# ing916 register map
Vendor: INGChips; Series: ing916xx; File version: 522
CPU: CM4 r0p1, little endian, MPU, FPU, VTOR, 5 interrupt priority bits
Registers are 32-bit, read-write, reset 0x0 unless marked. A register's access mark holds for its fields unless they carry their own. Offsets are from the block's base; [hi:lo] are bit positions; {n}, {i} and the like mark numbered series.

## sadc
Base 0x4000F000
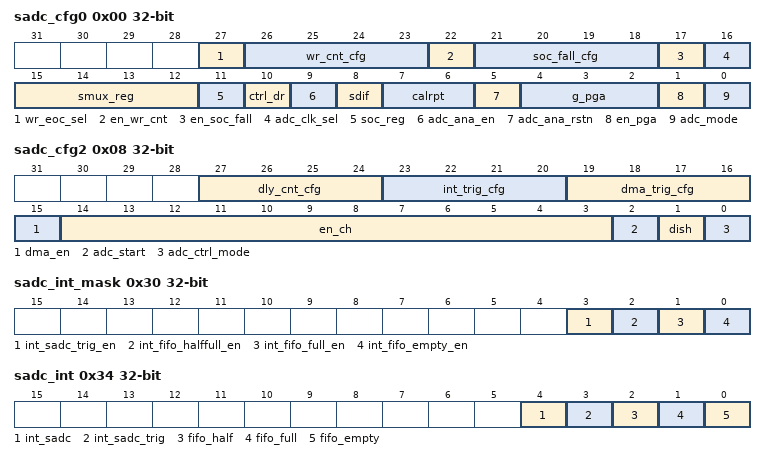
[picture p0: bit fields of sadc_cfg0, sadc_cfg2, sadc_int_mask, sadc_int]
0x00 sadc_cfg0 — reg description:
  [27] wr_eoc_sel — reg description:
  [26:23] wr_cnt_cfg — reg description:
  [22] en_wr_cnt — reg description:
  [21:18] soc_fall_cfg — reg description:
  [17] en_soc_fall — reg description:
  [16] adc_clk_sel — reg description:
  [15:12] smux_reg — reg description:
  [11] soc_reg — reg description:
  [10] ctrl_dr — reg description:
  [9] adc_ana_en — reg description:
  [8] sdif — reg description:
  [7:6] calrpt — reg description:
  [5] adc_ana_rstn — reg description:
  [4:2] g_pga — reg description:
  [1] en_pga — reg description:
  [0] adc_mode — reg description:
0x04 sadc_cfg1 — reg description:
  [31:0] loop_delay
0x08 sadc_cfg2 — reg description:
  [27:24] dly_cnt_cfg — reg description:
  [23:20] int_trig_cfg — reg description:
  [19:16] dma_trig_cfg — reg description:
  [15] dma_en — reg description:
  [14:3] en_ch — reg description:
  [2] adc_start — reg description:
  [1] dish — reg description:
  [0] adc_ctrl_mode — reg description:
0x0C sadc_data — reg description:
  [17:0] sadc_data
0x10 sadc_status0 — reg description:
0x30 sadc_int_mask — reg description:
  [3] int_sadc_trig_en — reg description:
  [2] int_fifo_halffull_en — reg description:
  [1] int_fifo_full_en — reg description:
  [0] int_fifo_empty_en — reg description:
0x34 sadc_int — reg description:
  [4] int_sadc — reg description:
  [3] int_sadc_trig — reg description:
  [2] fifo_half — reg description:
  [1] fifo_full — reg description:
  [0] fifo_empty — reg description:

## aon1_ctrl
Base 0x40102000
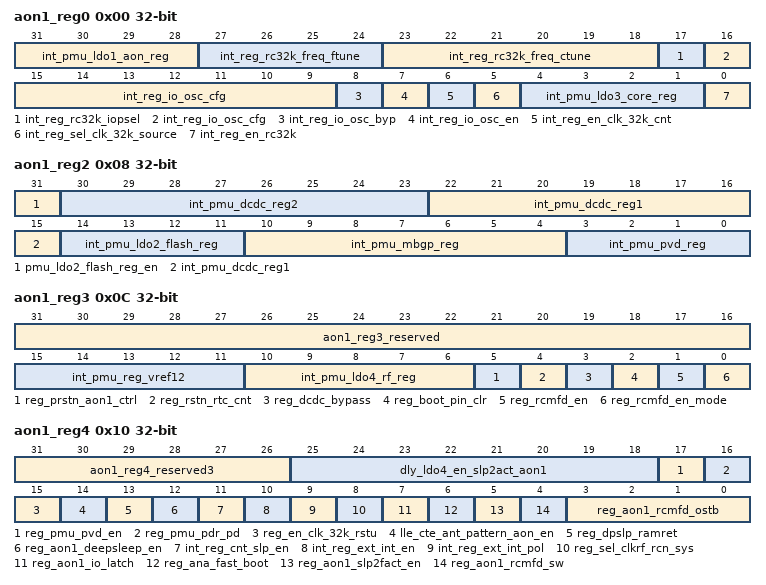
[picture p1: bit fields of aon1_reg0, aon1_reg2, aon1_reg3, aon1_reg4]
0x00 aon1_reg0 — reg description:
  [31:28] int_pmu_ldo1_aon_reg — reg description:
  [27:24] int_reg_rc32k_freq_ftune — reg description:
  [23:18] int_reg_rc32k_freq_ctune — reg description:
  [17] int_reg_rc32k_iopsel — reg description:
  [16:9] int_reg_io_osc_cfg — reg description:
  [8] int_reg_io_osc_byp — reg description:
  [7] int_reg_io_osc_en — reg description:
  [6] int_reg_en_clk_32k_cnt — reg description:
  [5] int_reg_sel_clk_32k_source — reg description:
  [4:1] int_pmu_ldo3_core_reg — reg description:
  [0] int_reg_en_rc32k — reg description:
0x04 aon1_reg1 — reg description:
  [31:0] int_reg_cnt_tgt
0x08 aon1_reg2 — reg description:
  [31] pmu_ldo2_flash_reg_en — reg description:
  [30:23] int_pmu_dcdc_reg2 — reg description:
  [22:15] int_pmu_dcdc_reg1 — reg description:
  [14:11] int_pmu_ldo2_flash_reg — reg description:
  [10:4] int_pmu_mbgp_reg — reg description:
  [3:0] int_pmu_pvd_reg — reg description:
0x0C aon1_reg3 — reg description:
  [31:16] aon1_reg3_reserved — reg description:
  [15:11] int_pmu_reg_vref12 — reg description:
  [10:6] int_pmu_ldo4_rf_reg — reg description:
  [5] reg_prstn_aon1_ctrl — reg description:
  [4] reg_rstn_rtc_cnt — reg description:
  [3] reg_dcdc_bypass — reg description:
  [2] reg_boot_pin_clr — reg description:
  [1] reg_rcmfd_en — reg description:
  [0] reg_rcmfd_en_mode — reg description:
0x10 aon1_reg4 — reg description:
  [31:26] aon1_reg4_reserved3 — reg description:
  [25:18] dly_ldo4_en_slp2act_aon1 — reg description:
  [17] reg_pmu_pvd_en — reg description:
  [16] reg_pmu_pdr_pd — reg description:
  [15] reg_en_clk_32k_rstu — reg description:
  [14] lle_cte_ant_pattern_aon_en — reg description:
  [13] reg_dpslp_ramret — reg description:
  [12] reg_aon1_deepsleep_en — reg description:
  [11] int_reg_cnt_slp_en — reg description:
  [10] int_reg_ext_int_en — reg description:
  [9] int_reg_ext_int_pol — reg description:
  [8] reg_sel_clkrf_rcn_sys — reg description:
  [7] reg_aon1_io_latch — reg description:
  [6] reg_ana_fast_boot — reg description:
  [5] reg_aon1_slp2fact_en — reg description:
  [4] reg_aon1_rcmfd_sw — reg description:
  [3:0] reg_aon1_rcmfd_ostb — reg description:
0x14 aon1_boot — reg description:
  [31:0] reg_aon1_boot
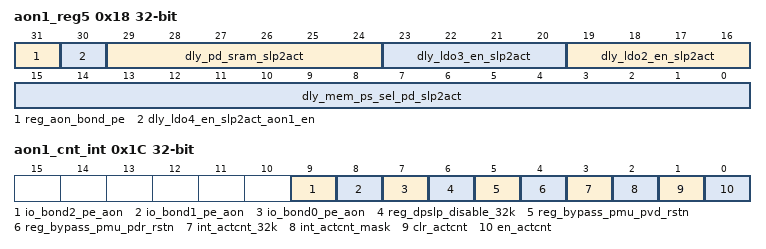
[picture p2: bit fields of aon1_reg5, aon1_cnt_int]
0x18 aon1_reg5 — reg description:
  [31] reg_aon_bond_pe — reg description:
  [30] dly_ldo4_en_slp2act_aon1_en — reg description:
  [29:24] dly_pd_sram_slp2act — reg description:
  [23:20] dly_ldo3_en_slp2act — reg description:
  [19:16] dly_ldo2_en_slp2act — reg description:
  [15:0] dly_mem_ps_sel_pd_slp2act — reg description:
0x1C aon1_cnt_int — reg description:
  [9] io_bond2_pe_aon — reg description:
  [8] io_bond1_pe_aon — reg description:
  [7] io_bond0_pe_aon — reg description:
  [6] reg_dpslp_disable_32k — reg description:
  [5] reg_bypass_pmu_pvd_rstn — reg description:
  [4] reg_bypass_pmu_pdr_rstn — reg description:
  [3] int_actcnt_32k — reg description:
  [2] int_actcnt_mask — reg description:
  [1] clr_actcnt — reg description:
  [0] en_actcnt — reg description:

## PDM
Base 0x40008000
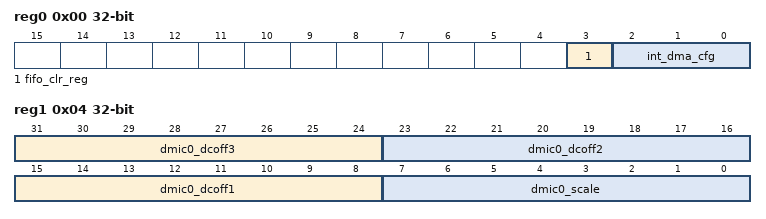
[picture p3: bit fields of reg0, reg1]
0x00 reg0 — reg description:
  [3] fifo_clr_reg — reg description:
  [2:0] int_dma_cfg — reg description:
0x04 reg1 — reg description:
  [31:24] dmic0_dcoff3 — reg description:
  [23:16] dmic0_dcoff2 — reg description:
  [15:8] dmic0_dcoff1 — reg description:
  [7:0] dmic0_scale — reg description:
0x20 reg8 — reg description:
0x24 reg9 — reg description:
  [31:0] data

## qdec
Base 0x40009000
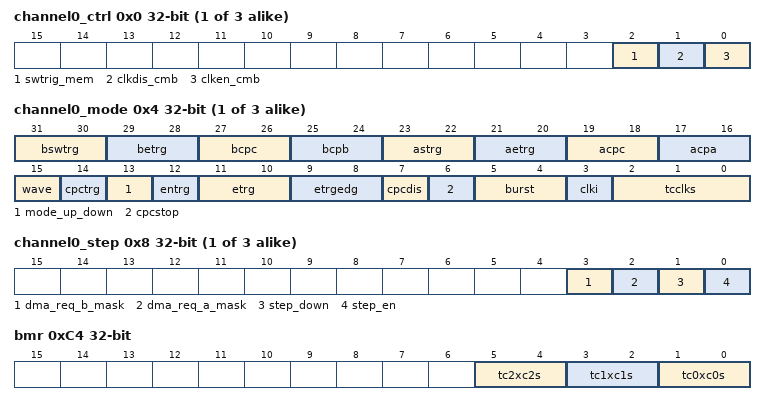
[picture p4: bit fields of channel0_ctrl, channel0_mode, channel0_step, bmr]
{0x0+0x40*i} channel{i}_ctrl (i=0..2) — reg description:
  [2] swtrig_mem — reg description:
  [1] clkdis_cmb — reg description:
  [0] clken_cmb — reg description:
{0x4+0x40*i} channel{i}_mode (i=0..2) — reg description:
  [31:30] bswtrg — reg description:
  [29:28] betrg — reg description:
  [27:26] bcpc — reg description:
  [25:24] bcpb — reg description:
  [23:22] astrg — reg description:
  [21:20] aetrg — reg description:
  [19:18] acpc — reg description:
  [17:16] acpa — reg description:
  [15] wave — reg description:
  [14] cpctrg — reg description:
  [13] mode_up_down — reg description:
  [12] entrg — reg description:
  [11:10] etrg — reg description:
  [9:8] etrgedg — reg description:
  [7] cpcdis — reg description:
  [6] cpcstop — reg description:
  [5:4] burst — reg description:
  [3] clki — reg description:
  [2:0] tcclks — reg description:
{0x8+0x40*i} channel{i}_step (i=0..2) — reg description:
  [3] dma_req_b_mask — reg description:
  [2] dma_req_a_mask — reg description:
  [1] step_down — reg description:
  [0] step_en — reg description:
{0xC+0x40*i} channel{i}_read_rab (i=0..2) — reg description:
  [15:0] tc_rab
{0x10+0x40*i} channel{i}_read_tc (i=0..2) — reg description:
  [15:0] tc_cv
{0x14+0x40*i} channel{i}write_a (i=0..2) — reg description:
  [15:0] tc_ra
{0x18+0x40*i} channel{i}write_b (i=0..2) — reg description:
  [15:0] tc_rb
0x1C channel0write_c — reg description:
  [15:0] tc_rc
{0x20+0x40*i} channel{i}tiob0_rd (i=0..2) — reg description:
  [9:0] tc_sr
{0x24+0x40*i} channel{i}int_en (i=0..2) — reg description:
  [9:0] tc_imr_enable
{0x28+0x40*i} channel{i}int_dis (i=0..2) — reg description:
  [9:0] tc_imr_disable
{0x2C+0x40*i} channel{i}int_rd (i=0..2) — reg description:
  [9:0] tc_imr
0x5C channel1write_c — reg description:
  [15:0] tc_rc
0x9C channel3write_c — reg description:
  [15:0] tc_rc
0xC0 bcr — reg description:
  [0] bcr
0xC4 bmr — reg description:
  [5:4] tc2xc2s — reg description:
  [3:2] tc1xc1s — reg description:
  [1:0] tc0xc0s — reg description:
0xC8 qdec_inten — reg description:
  [3:0] qdec_int_en
0xCC qdec_intdis — reg description:
  [3:0] qdec_int_dis
0xD0 qdec_inten_rd — reg description:
  [3:0] qdec_int_mask
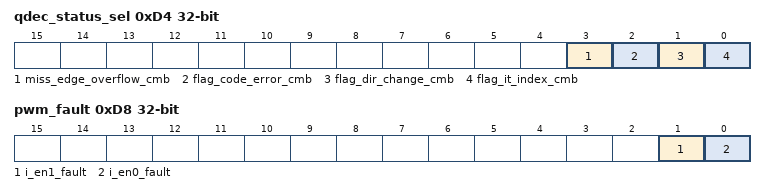
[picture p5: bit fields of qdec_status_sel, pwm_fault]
0xD4 qdec_status_sel — reg description:
  [3] miss_edge_overflow_cmb — reg description:
  [2] flag_code_error_cmb — reg description:
  [1] flag_dir_change_cmb — reg description:
  [0] flag_it_index_cmb — reg description:
0xD8 pwm_fault — reg description:
  [1] i_en1_fault — reg description:
  [0] i_en0_fault — reg description:
0xE0 dummy — reg description:
0xE4 wpmode — reg description:
  [0] wr_protected
0xEC addrsize — reg description:
0xF0 name1 — reg description:
0xF4 name2 — reg description:
0xF8 FEATURES — reg description:
